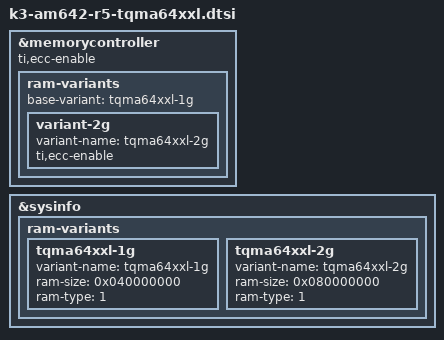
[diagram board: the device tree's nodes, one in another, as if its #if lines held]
// SPDX-License-Identifier: GPL-2.0-only
/*
 * Copyright (C) 2021 Texas Instruments Incorporated - https://www.ti.com/
 * Copyright (c) 2022-2023 TQ-Systems GmbH <u-boot@ew.tq-group.com>, D-82229 Seefeld, Germany.
 */

#include "k3-am64-r5.dtsi"
#include "k3-am64-tqma64xxl-1g-lp4-1600MTs.dtsi"
#include "k3-am64-ddr.dtsi"

#include <config.h>

&memorycontroller {
#ifdef CONFIG_K3_INLINE_ECC
	ti,ecc-enable;
#endif

	ram-variants {
		base-variant = "tqma64xxl-1g";
		bootph-pre-ram;

		variant-2g {
			variant-name = "tqma64xxl-2g";

#ifdef CONFIG_K3_INLINE_ECC
			ti,ecc-enable;
#endif

			#include "k3-am64-tqma64xxl-2g-lp4-1600MTs-patch.dtsi"
		};
	};
};

&sysinfo {
	ram-variants {
		bootph-pre-ram;

		tqma64xxl-1g {
			variant-name = "tqma64xxl-1g";
			ram-size = /bits/ 64 <0x040000000>;
			ram-type = <1>;
			bootph-pre-ram;
		};

		tqma64xxl-2g {
			variant-name = "tqma64xxl-2g";
			ram-size = /bits/ 64 <0x080000000>;
			ram-type = <1>;
			bootph-pre-ram;
		};
	};
};
